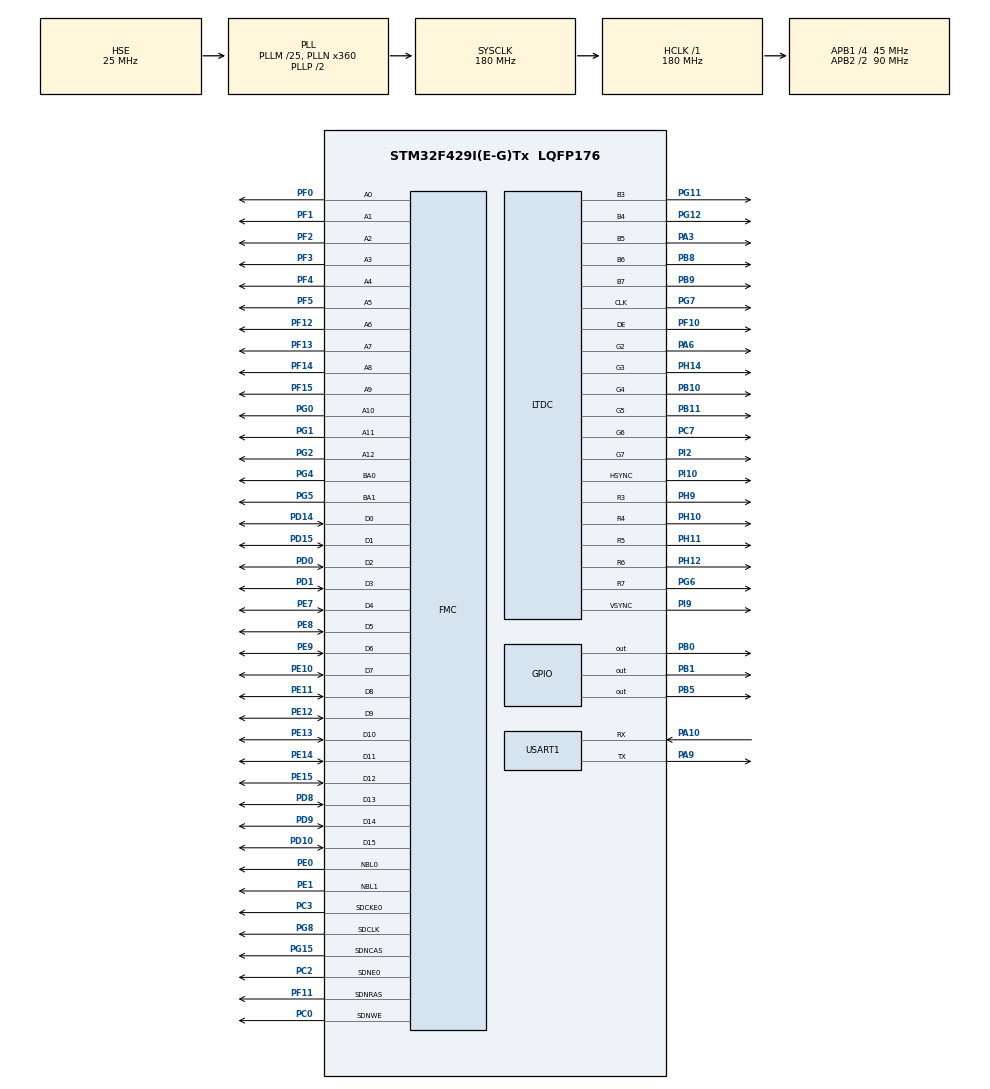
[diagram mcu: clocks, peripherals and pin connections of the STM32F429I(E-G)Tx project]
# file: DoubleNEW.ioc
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DMA2D.ColorMode=DMA2D_OUTPUT_RGB565
FMC.CASLatency1=FMC_SDRAM_CAS_LATENCY_3
FMC.ColumnBitsNumber1=FMC_SDRAM_COLUMN_BITS_NUM_9
FMC.ExitSelfRefreshDelay1=8
FMC.LoadToActiveDelay1=2
FMC.RCDDelay1=2
FMC.RPDelay1=2
FMC.ReadBurst1=FMC_SDRAM_RBURST_ENABLE
FMC.ReadPipeDelay1=FMC_SDRAM_RPIPE_DELAY_1
FMC.RowCycleDelay1=6
FMC.SDClockPeriod1=FMC_SDRAM_CLOCK_PERIOD_2
FMC.SelfRefreshTime1=6
FMC.WriteRecoveryTime1=4
FREERTOS.Tasks01=LEDTask,24,4096,StartLEDTask,Default,NULL,Dynamic,NULL,NULL;UARTTask,24,512,StartUARTTask,Default,NULL,Dynamic,NULL,NULL;GUITask,24,4096,StartGUITask,Default,NULL,Dynamic,NULL,NULL
FREERTOS.configTOTAL_HEAP_SIZE=65536
LTDC.ActiveH=272
LTDC.ActiveW=480
LTDC.Alpha_L0=255
LTDC.FBStartAdress_L0=0xc0000000
LTDC.HBP=40
LTDC.HFP=5
LTDC.HSync=1
LTDC.ImageHeight_L0=272
LTDC.ImageWidth_L0=480
LTDC.Layers=0
LTDC.PixelFormat_L0=LTDC_PIXEL_FORMAT_RGB565
LTDC.VBP=8
LTDC.VFP=8
LTDC.VSync=1
LTDC.WindowX1_L0=480
LTDC.WindowY1_L0=272
Mcu.Family=STM32F4
Mcu.Name=STM32F429I(E-G)Tx
Mcu.Package=LQFP176
NVIC.DMA2D_IRQn=true\:5\:0\:false\:false\:true\:true\:true\:true
NVIC.FMC_IRQn=true\:5\:0\:false\:false\:true\:true\:true\:true
NVIC.LTDC_ER_IRQn=true\:5\:0\:false\:false\:true\:true\:true\:true
NVIC.LTDC_IRQn=true\:5\:0\:false\:false\:true\:true\:true\:true
NVIC.PriorityGroup=NVIC_PRIORITYGROUP_4
NVIC.TIM4_IRQn=true\:0\:0\:false\:false\:true\:false\:false\:true
NVIC.TIM7_IRQn=true\:5\:0\:false\:false\:true\:true\:true\:true
NVIC.TimeBase=TIM4_IRQn
NVIC.TimeBaseIP=TIM4
PA10.Mode=Asynchronous
PA10.Signal=USART1_RX
PA13.Mode=Serial_Wire
PA13.Signal=SYS_JTMS-SWDIO
PA14.Mode=Serial_Wire
PA14.Signal=SYS_JTCK-SWCLK
PA3.Mode=RGB565
PA3.Signal=LTDC_B5
PA6.Mode=RGB565
PA6.Signal=LTDC_G2
PA9.Mode=Asynchronous
PA9.Signal=USART1_TX
PB0.Signal=GPIO_Output
PB1.Signal=GPIO_Output
PB10.Mode=RGB565
PB10.Signal=LTDC_G4
PB11.Mode=RGB565
PB11.Signal=LTDC_G5
PB5.PinState=GPIO_PIN_SET
PB5.Signal=GPIO_Output
PB8.Mode=RGB565
PB8.Signal=LTDC_B6
PB9.Mode=RGB565
PB9.Signal=LTDC_B7
PC0.Signal=FMC_SDNWE
PC14/OSC32_IN.Mode=LSE-External-Oscillator
PC14/OSC32_IN.Signal=RCC_OSC32_IN
PC15/OSC32_OUT.Mode=LSE-External-Oscillator
PC15/OSC32_OUT.Signal=RCC_OSC32_OUT
PC2.Mode=SdramChipSelect1_1
PC2.Signal=FMC_SDNE0
PC3.Mode=SdramChipSelect1_1
PC3.Signal=FMC_SDCKE0
PC7.Mode=RGB565
PC7.Signal=LTDC_G6
PD0.Signal=FMC_D2_DA2
PD1.Signal=FMC_D3_DA3
PD10.Signal=FMC_D15_DA15
PD14.Signal=FMC_D0_DA0
PD15.Signal=FMC_D1_DA1
PD8.Signal=FMC_D13_DA13
PD9.Signal=FMC_D14_DA14
PE0.Signal=FMC_NBL0
PE1.Signal=FMC_NBL1
PE10.Signal=FMC_D7_DA7
PE11.Signal=FMC_D8_DA8
PE12.Signal=FMC_D9_DA9
PE13.Signal=FMC_D10_DA10
PE14.Signal=FMC_D11_DA11
PE15.Signal=FMC_D12_DA12
PE7.Signal=FMC_D4_DA4
PE8.Signal=FMC_D5_DA5
PE9.Signal=FMC_D6_DA6
PF0.Signal=FMC_A0
PF1.Signal=FMC_A1
PF10.Mode=RGB565
PF10.Signal=LTDC_DE
PF11.Signal=FMC_SDNRAS
PF12.Signal=FMC_A6
PF13.Signal=FMC_A7
PF14.Signal=FMC_A8
PF15.Signal=FMC_A9
PF2.Signal=FMC_A2
PF3.Signal=FMC_A3
PF4.Signal=FMC_A4
PF5.Signal=FMC_A5
PG0.Signal=FMC_A10
PG1.Signal=FMC_A11
PG11.Mode=RGB565
PG11.Signal=LTDC_B3
PG12.Mode=RGB565
PG12.Signal=LTDC_B4
PG15.Signal=FMC_SDNCAS
PG2.Signal=FMC_A12
PG4.Signal=FMC_A14_BA0
PG5.Signal=FMC_A15_BA1
PG6.Mode=RGB565
PG6.Signal=LTDC_R7
PG7.Mode=RGB565
PG7.Signal=LTDC_CLK
PG8.Signal=FMC_SDCLK
PH0/OSC_IN.Mode=HSE-External-Oscillator
PH0/OSC_IN.Signal=RCC_OSC_IN
PH1/OSC_OUT.Mode=HSE-External-Oscillator
PH1/OSC_OUT.Signal=RCC_OSC_OUT
PH10.Mode=RGB565
PH10.Signal=LTDC_R4
PH11.Mode=RGB565
PH11.Signal=LTDC_R5
PH12.Mode=RGB565
PH12.Signal=LTDC_R6
PH14.Mode=RGB565
PH14.Signal=LTDC_G3
PH9.Mode=RGB565
PH9.Signal=LTDC_R3
PI10.Mode=RGB565
PI10.Signal=LTDC_HSYNC
PI2.Mode=RGB565
PI2.Signal=LTDC_G7
PI9.Mode=RGB565
PI9.Signal=LTDC_VSYNC
ProjectManager.HeapSize=0x200
ProjectManager.StackSize=0x400
ProjectManager.TargetToolchain=EWARM V8.32
RCC.48MHZClocksFreq_Value=90000000
RCC.AHBFreq_Value=180000000
RCC.APB1CLKDivider=RCC_HCLK_DIV4
RCC.APB1Freq_Value=45000000
RCC.APB1TimFreq_Value=90000000
RCC.APB2CLKDivider=RCC_HCLK_DIV2
RCC.APB2Freq_Value=90000000
RCC.APB2TimFreq_Value=180000000
RCC.CortexFreq_Value=180000000
RCC.HCLKFreq_Value=180000000
RCC.HSE_VALUE=25000000
RCC.HSI_VALUE=16000000
RCC.PLLM=25
RCC.PLLN=360
RCC.PLLSAIN=100
RCC.PLLSourceVirtual=RCC_PLLSOURCE_HSE
RCC.SYSCLKFreq_VALUE=180000000
RCC.SYSCLKSource=RCC_SYSCLKSOURCE_PLLCLK
RCC.VCOOutputFreq_Value=360000000
SH.FMC_A0.0=FMC_A0,13b-sda1
SH.FMC_A1.0=FMC_A1,13b-sda1
SH.FMC_A10.0=FMC_A10,13b-sda1
SH.FMC_A11.0=FMC_A11,13b-sda1
SH.FMC_A12.0=FMC_A12,13b-sda1
SH.FMC_A14_BA0.0=FMC_BA0,FourSdramBanks1
SH.FMC_A15_BA1.0=FMC_BA1,FourSdramBanks1
SH.FMC_A2.0=FMC_A2,13b-sda1
SH.FMC_A3.0=FMC_A3,13b-sda1
SH.FMC_A4.0=FMC_A4,13b-sda1
SH.FMC_A5.0=FMC_A5,13b-sda1
SH.FMC_A6.0=FMC_A6,13b-sda1
SH.FMC_A7.0=FMC_A7,13b-sda1
SH.FMC_A8.0=FMC_A8,13b-sda1
SH.FMC_A9.0=FMC_A9,13b-sda1
SH.FMC_D0_DA0.0=FMC_D0,sd-16b-d1
SH.FMC_D10_DA10.0=FMC_D10,sd-16b-d1
SH.FMC_D11_DA11.0=FMC_D11,sd-16b-d1
SH.FMC_D12_DA12.0=FMC_D12,sd-16b-d1
SH.FMC_D13_DA13.0=FMC_D13,sd-16b-d1
SH.FMC_D14_DA14.0=FMC_D14,sd-16b-d1
SH.FMC_D15_DA15.0=FMC_D15,sd-16b-d1
SH.FMC_D1_DA1.0=FMC_D1,sd-16b-d1
SH.FMC_D2_DA2.0=FMC_D2,sd-16b-d1
SH.FMC_D3_DA3.0=FMC_D3,sd-16b-d1
SH.FMC_D4_DA4.0=FMC_D4,sd-16b-d1
SH.FMC_D5_DA5.0=FMC_D5,sd-16b-d1
SH.FMC_D6_DA6.0=FMC_D6,sd-16b-d1
SH.FMC_D7_DA7.0=FMC_D7,sd-16b-d1
SH.FMC_D8_DA8.0=FMC_D8,sd-16b-d1
SH.FMC_D9_DA9.0=FMC_D9,sd-16b-d1
SH.FMC_NBL0.0=FMC_NBL0,Sd2ByteEnable1
SH.FMC_NBL1.0=FMC_NBL1,Sd2ByteEnable1
SH.FMC_SDCLK.0=FMC_SDCLK,13b-sda1
SH.FMC_SDNCAS.0=FMC_SDNCAS,13b-sda1
SH.FMC_SDNRAS.0=FMC_SDNRAS,13b-sda1
SH.FMC_SDNWE.0=FMC_SDNWE,13b-sda1
STMicroelectronics.X-CUBE-TOUCHGFX.4.16.1.ApplicationCcGraphicsJjApplication=TouchGFXOoGenerator
STMicroelectronics.X-CUBE-TOUCHGFX.4.16.1.tgfx_address1=0xC0000000
STMicroelectronics.X-CUBE-TOUCHGFX.4.16.1.tgfx_address2=0xC0050000
STMicroelectronics.X-CUBE-TOUCHGFX.4.16.1.tgfx_buffering_strategy=Single
STMicroelectronics.X-CUBE-TOUCHGFX.4.16.1.tgfx_custom_height=272
STMicroelectronics.X-CUBE-TOUCHGFX.4.16.1.tgfx_display_interface=disp_ltdc
STMicroelectronics.X-CUBE-TOUCHGFX.4.16.1.tgfx_hardware_accelerator=dma_2d
STMicroelectronics.X-CUBE-TOUCHGFX.4.16.1.tgfx_location=By Address
STMicroelectronics.X-CUBE-TOUCHGFX.4.16.1.tgfx_vsync=vsync_ltdc
USART1.VirtualMode=VM_ASYNC
VP_CRC_VS_CRC.Mode=CRC_Activate
VP_DMA2D_VS_DMA2D.Mode=DMA2D_Activate
VP_FREERTOS_VS_CMSIS_V2.Mode=CMSIS_V2
VP_STMicroelectronics.X-CUBE-TOUCHGFX_VS_GraphicsJjApplication_4.16.1.Mode=GraphicsJjApplication
VP_SYS_VS_tim4.Mode=TIM4
VP_TIM7_VS_ClockSourceINT.Mode=Enable_Timer
board=custom

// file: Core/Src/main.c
/* USER CODE BEGIN Header */
/**
  ******************************************************************************
  * @file           : main.c
  * @brief          : Main program body
  ******************************************************************************
  * @attention
  *
  * <h2><center>&copy; Copyright (c) 2021 STMicroelectronics.
  * All rights reserved.</center></h2>
  *
  * This software component is licensed by ST under Ultimate Liberty license
  * SLA0044, the "License"; You may not use this file except in compliance with
  * the License. You may obtain a copy of the License at:
  *                             www.st.com/SLA0044
  *
  ******************************************************************************
  */
/* USER CODE END Header */
#include "main.h"
#include "cmsis_os.h"
#include "crc.h"
#include "dma2d.h"
#include "ltdc.h"
#include "tim.h"
#include "usart.h"
#include "gpio.h"
#include "fmc.h"
#include "app_touchgfx.h"

void SystemClock_Config(void);
void MX_FREERTOS_Init(void);

int main(void)
{

  /* MCU Configuration--------------------------------------------------------*/

  /* Reset of all peripherals, Initializes the Flash interface and the Systick. */
  HAL_Init();

  /* Configure the system clock */
  SystemClock_Config();

  /* Initialize all configured peripherals */
  MX_GPIO_Init();
  MX_DMA2D_Init();
  MX_FMC_Init();
  MX_TIM7_Init();
  MX_USART1_UART_Init();
  MX_CRC_Init();
  MX_LTDC_Init();
  MX_TouchGFX_Init();

  /* Init scheduler */
  osKernelInitialize();  /* Call init function for freertos objects (in freertos.c) */
  MX_FREERTOS_Init();
  /* Start scheduler */
  osKernelStart();

  /* We should never get here as control is now taken by the scheduler */
  /* Infinite loop */
  while (1)
  {

  }
}

void SystemClock_Config(void)
{
  RCC_OscInitTypeDef RCC_OscInitStruct = {0};
  RCC_ClkInitTypeDef RCC_ClkInitStruct = {0};
  RCC_PeriphCLKInitTypeDef PeriphClkInitStruct = {0};

  /** Configure the main internal regulator output voltage
  */
  __HAL_RCC_PWR_CLK_ENABLE();
  __HAL_PWR_VOLTAGESCALING_CONFIG(PWR_REGULATOR_VOLTAGE_SCALE1);
  /** Initializes the RCC Oscillators according to the specified parameters
  * in the RCC_OscInitTypeDef structure.
  */
  RCC_OscInitStruct.OscillatorType = RCC_OSCILLATORTYPE_HSE;
  RCC_OscInitStruct.HSEState = RCC_HSE_ON;
  RCC_OscInitStruct.PLL.PLLState = RCC_PLL_ON;
  RCC_OscInitStruct.PLL.PLLSource = RCC_PLLSOURCE_HSE;
  RCC_OscInitStruct.PLL.PLLM = 25;
  RCC_OscInitStruct.PLL.PLLN = 360;
  RCC_OscInitStruct.PLL.PLLP = RCC_PLLP_DIV2;
  RCC_OscInitStruct.PLL.PLLQ = 4;
  if (HAL_RCC_OscConfig(&RCC_OscInitStruct) != HAL_OK)
  {
    Error_Handler();
  }
  /** Activate the Over-Drive mode
  */
  if (HAL_PWREx_EnableOverDrive() != HAL_OK)
  {
    Error_Handler();
  }
  /** Initializes the CPU, AHB and APB buses clocks
  */
  RCC_ClkInitStruct.ClockType = RCC_CLOCKTYPE_HCLK|RCC_CLOCKTYPE_SYSCLK
                              |RCC_CLOCKTYPE_PCLK1|RCC_CLOCKTYPE_PCLK2;
  RCC_ClkInitStruct.SYSCLKSource = RCC_SYSCLKSOURCE_PLLCLK;
  RCC_ClkInitStruct.AHBCLKDivider = RCC_SYSCLK_DIV1;
  RCC_ClkInitStruct.APB1CLKDivider = RCC_HCLK_DIV4;
  RCC_ClkInitStruct.APB2CLKDivider = RCC_HCLK_DIV2;

  if (HAL_RCC_ClockConfig(&RCC_ClkInitStruct, FLASH_LATENCY_5) != HAL_OK)
  {
    Error_Handler();
  }
  PeriphClkInitStruct.PeriphClockSelection = RCC_PERIPHCLK_LTDC;
  PeriphClkInitStruct.PLLSAI.PLLSAIN = 100;
  PeriphClkInitStruct.PLLSAI.PLLSAIR = 2;
  PeriphClkInitStruct.PLLSAIDivR = RCC_PLLSAIDIVR_2;
  if (HAL_RCCEx_PeriphCLKConfig(&PeriphClkInitStruct) != HAL_OK)
  {
    Error_Handler();
  }
}

 /**
  * @brief  Period elapsed callback in non blocking mode
  * @note   This function is called  when TIM4 interrupt took place, inside
  * HAL_TIM_IRQHandler(). It makes a direct call to HAL_IncTick() to increment
  * a global variable "uwTick" used as application time base.
  * @param  htim : TIM handle
  * @retval None
  */
void HAL_TIM_PeriodElapsedCallback(TIM_HandleTypeDef *htim)
{
  if (htim->Instance == TIM4) {
    HAL_IncTick();
  }
}

void Error_Handler(void)
{
  __disable_irq();
  while (1)
  {
  }
}

/************************ (C) COPYRIGHT STMicroelectronics *****END OF FILE****/

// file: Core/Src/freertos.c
/* USER CODE BEGIN Header */
/**
  ******************************************************************************
  * File Name          : freertos.c
  * Description        : Code for freertos applications
  ******************************************************************************
  * @attention
  *
  * <h2><center>&copy; Copyright (c) 2021 STMicroelectronics.
  * All rights reserved.</center></h2>
  *
  * This software component is licensed by ST under Ultimate Liberty license
  * SLA0044, the "License"; You may not use this file except in compliance with
  * the License. You may obtain a copy of the License at:
  *                             www.st.com/SLA0044
  *
  ******************************************************************************
  */
/* USER CODE END Header */

#include "FreeRTOS.h"
#include "task.h"
#include "main.h"
#include "cmsis_os.h"

/* USER CODE BEGIN Variables */
extern UART_HandleTypeDef huart1;
/* USER CODE END Variables */
/* Definitions for LEDTask */
osThreadId_t LEDTaskHandle;
const osThreadAttr_t LEDTask_attributes = {
  .name = "LEDTask",
  .stack_size = 4096 * 4,
  .priority = (osPriority_t) osPriorityNormal,
};
/* Definitions for UARTTask */
osThreadId_t UARTTaskHandle;
const osThreadAttr_t UARTTask_attributes = {
  .name = "UARTTask",
  .stack_size = 512 * 4,
  .priority = (osPriority_t) osPriorityNormal,
};
/* Definitions for GUITask */
osThreadId_t GUITaskHandle;
const osThreadAttr_t GUITask_attributes = {
  .name = "GUITask",
  .stack_size = 4096 * 4,
  .priority = (osPriority_t) osPriorityNormal,
};

void StartLEDTask(void *argument);
void StartUARTTask(void *argument);
void StartGUITask(void *argument);

void MX_FREERTOS_Init(void); /* (MISRA C 2004 rule 8.1) */

void MX_FREERTOS_Init(void) {

  /* Create the thread(s) */
  /* creation of LEDTask */
  LEDTaskHandle = osThreadNew(StartLEDTask, NULL, &LEDTask_attributes);

  /* creation of UARTTask */
  UARTTaskHandle = osThreadNew(StartUARTTask, NULL, &UARTTask_attributes);

  /* creation of GUITask */
  GUITaskHandle = osThreadNew(StartGUITask, NULL, &GUITask_attributes);

}

void StartLEDTask(void *argument)
{
  /* USER CODE BEGIN StartLEDTask */
  /* Infinite loop */
  for(;;)
  {
	HAL_GPIO_WritePin(GPIOB, GPIO_PIN_0, GPIO_PIN_RESET);
	HAL_GPIO_WritePin(GPIOB, GPIO_PIN_1, GPIO_PIN_RESET);
	osDelay(100);
	HAL_GPIO_WritePin(GPIOB, GPIO_PIN_0, GPIO_PIN_SET);
	HAL_GPIO_WritePin(GPIOB, GPIO_PIN_1, GPIO_PIN_SET);
	osDelay(100);
  }
  /* USER CODE END StartLEDTask */
}

void StartUARTTask(void *argument)
{
  /* USER CODE BEGIN StartUARTTask */
	uint8_t TxData[20]= "usart1 transmit!\n";
  /* Infinite loop */
  for(;;)
  {
    HAL_UART_Transmit(&huart1,TxData,20,0xffff);
    osDelay(500);
  }
  /* USER CODE END StartUARTTask */
}

void StartGUITask(void *argument)
{
  /* USER CODE BEGIN StartGUITask */
  /* Infinite loop */

  MX_TouchGFX_Process();
  /* USER CODE END StartGUITask */
}

/************************ (C) COPYRIGHT STMicroelectronics *****END OF FILE****/
